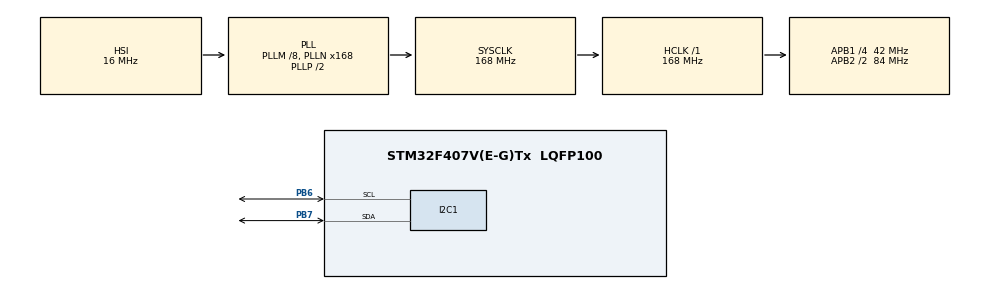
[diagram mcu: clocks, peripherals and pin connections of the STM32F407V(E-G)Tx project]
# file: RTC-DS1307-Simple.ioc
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Mcu.Family=STM32F4
Mcu.Name=STM32F407V(E-G)Tx
Mcu.Package=LQFP100
NVIC.PriorityGroup=NVIC_PRIORITYGROUP_4
PB6.Mode=I2C
PB6.Signal=I2C1_SCL
PB7.Mode=I2C
PB7.Signal=I2C1_SDA
ProjectManager.HeapSize=0x200
ProjectManager.StackSize=0x400
ProjectManager.TargetToolchain=MDK-ARM V5.27
RCC.48MHZClocksFreq_Value=84000000
RCC.AHBFreq_Value=168000000
RCC.APB1CLKDivider=RCC_HCLK_DIV4
RCC.APB1Freq_Value=42000000
RCC.APB1TimFreq_Value=84000000
RCC.APB2CLKDivider=RCC_HCLK_DIV2
RCC.APB2Freq_Value=84000000
RCC.APB2TimFreq_Value=168000000
RCC.CortexFreq_Value=168000000
RCC.HCLKFreq_Value=168000000
RCC.HSE_VALUE=25000000
RCC.HSI_VALUE=16000000
RCC.LSE_VALUE=32768
RCC.PLLM=8
RCC.PLLN=168
RCC.SYSCLKFreq_VALUE=168000000
RCC.SYSCLKSource=RCC_SYSCLKSOURCE_PLLCLK
RCC.VCOOutputFreq_Value=336000000
board=custom

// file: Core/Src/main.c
/* USER CODE BEGIN Header */
/**
  ******************************************************************************
  * @file           : main.c
  * @brief          : Main program body
  ******************************************************************************
  * @attention
  *
  * <h2><center>&copy; Copyright (c) 2023 STMicroelectronics.
  * All rights reserved.</center></h2>
  *
  * This software component is licensed by ST under BSD 3-Clause license,
  * the "License"; You may not use this file except in compliance with the
  * License. You may obtain a copy of the License at:
  *                        opensource.org/licenses/BSD-3-Clause
  *
  ******************************************************************************
  */
/* USER CODE END Header */
#include "main.h"
#include "i2c.h"
#include "gpio.h"

/* USER CODE BEGIN Includes */
#include "ALCD.h"
/* USER CODE END Includes */

/* USER CODE BEGIN PD */
#define DS1307_DEV_ADDR           0xD0
/* USER CODE END PD */

void SystemClock_Config(void);
/* USER CODE BEGIN PFP */
uint8_t RTC_isRunning(void);

void RTC_setTime(uint8_t h, uint8_t m, uint8_t s);
void RTC_setDate(uint8_t y, uint8_t m, uint8_t d, uint8_t weekDay);

void RTC_getTime(uint8_t* h, uint8_t* m, uint8_t* s);
void RTC_getDate(uint8_t* y, uint8_t* m, uint8_t* d, uint8_t* weekDay);

uint8_t bcdToBin(uint8_t val);
uint8_t binToBcd(uint8_t val);

/* USER CODE END PFP */

int main(void)
{
  /* USER CODE BEGIN 1 */
  uint8_t hour;
  uint8_t min;
  uint8_t sec;
  /* USER CODE END 1 */

  /* MCU Configuration--------------------------------------------------------*/

  /* Reset of all peripherals, Initializes the Flash interface and the Systick. */
  HAL_Init();

  /* Configure the system clock */
  SystemClock_Config();

  /* Initialize all configured peripherals */
  MX_GPIO_Init();
  MX_I2C1_Init();
  /* USER CODE BEGIN 2 */
  ALCD_init(16, 2);
  ALCD_clear();
  /* USER CODE END 2 */

  /* Infinite loop */
  /* USER CODE BEGIN WHILE */
  if (!RTC_isRunning()) {
    RTC_setDate(23, 12, 11, 3);
    RTC_setTime(13, 50, 24);
  }

  while (1)
  {

    RTC_getTime(&hour, &min, &sec);
    ALCD_printfXY(2, 0, "%02u:%02u:%02u", hour, min, sec);
    HAL_Delay(1000);
    /* USER CODE END WHILE */

  }
}

void SystemClock_Config(void)
{
  RCC_OscInitTypeDef RCC_OscInitStruct = {0};
  RCC_ClkInitTypeDef RCC_ClkInitStruct = {0};

  /** Configure the main internal regulator output voltage
  */
  __HAL_RCC_PWR_CLK_ENABLE();
  __HAL_PWR_VOLTAGESCALING_CONFIG(PWR_REGULATOR_VOLTAGE_SCALE1);
  /** Initializes the RCC Oscillators according to the specified parameters
  * in the RCC_OscInitTypeDef structure.
  */
  RCC_OscInitStruct.OscillatorType = RCC_OSCILLATORTYPE_HSI;
  RCC_OscInitStruct.HSIState = RCC_HSI_ON;
  RCC_OscInitStruct.HSICalibrationValue = RCC_HSICALIBRATION_DEFAULT;
  RCC_OscInitStruct.PLL.PLLState = RCC_PLL_ON;
  RCC_OscInitStruct.PLL.PLLSource = RCC_PLLSOURCE_HSI;
  RCC_OscInitStruct.PLL.PLLM = 8;
  RCC_OscInitStruct.PLL.PLLN = 168;
  RCC_OscInitStruct.PLL.PLLP = RCC_PLLP_DIV2;
  RCC_OscInitStruct.PLL.PLLQ = 4;
  if (HAL_RCC_OscConfig(&RCC_OscInitStruct) != HAL_OK)
  {
    Error_Handler();
  }
  /** Initializes the CPU, AHB and APB buses clocks
  */
  RCC_ClkInitStruct.ClockType = RCC_CLOCKTYPE_HCLK|RCC_CLOCKTYPE_SYSCLK
                              |RCC_CLOCKTYPE_PCLK1|RCC_CLOCKTYPE_PCLK2;
  RCC_ClkInitStruct.SYSCLKSource = RCC_SYSCLKSOURCE_PLLCLK;
  RCC_ClkInitStruct.AHBCLKDivider = RCC_SYSCLK_DIV1;
  RCC_ClkInitStruct.APB1CLKDivider = RCC_HCLK_DIV4;
  RCC_ClkInitStruct.APB2CLKDivider = RCC_HCLK_DIV2;

  if (HAL_RCC_ClockConfig(&RCC_ClkInitStruct, FLASH_LATENCY_5) != HAL_OK)
  {
    Error_Handler();
  }
}

/* USER CODE BEGIN 4 */
/**
 * 14 (Bin) -> 0x14 (BCD)
 * 37 (Bin) -> 0x37 (BCD)
 */
uint8_t bcdToBin(uint8_t val) {
  return (val & 0x0F) + (((val >> 4) & 0x0F) * 10);
}
uint8_t binToBcd(uint8_t val) {
  return (val % 10) | ((val / 10) << 4);
}

void RTC_setTime(uint8_t h, uint8_t m, uint8_t s) {
  uint8_t buf[3];
  buf[0] = binToBcd(s);
  buf[1] = binToBcd(m);
  buf[2] = binToBcd(h);
  HAL_I2C_Mem_Write(&hi2c1, DS1307_DEV_ADDR, 0, I2C_MEMADD_SIZE_8BIT, buf, sizeof(buf), 1000);
}
void RTC_setDate(uint8_t y, uint8_t m, uint8_t d, uint8_t weekDay) {
  uint8_t buf[4];
  buf[0] = binToBcd(weekDay);
  buf[1] = binToBcd(d);
  buf[2] = binToBcd(m);
  buf[3] = binToBcd(y);
  HAL_I2C_Mem_Write(&hi2c1, DS1307_DEV_ADDR, 3, I2C_MEMADD_SIZE_8BIT, buf, sizeof(buf), 1000);
}

void RTC_getTime(uint8_t* h, uint8_t* m, uint8_t* s) {
  uint8_t buf[3];
  HAL_I2C_Mem_Read(&hi2c1, DS1307_DEV_ADDR, 0, I2C_MEMADD_SIZE_8BIT, buf, sizeof(buf), 1000);

  *s = bcdToBin(buf[0]);
  *m = bcdToBin(buf[1]);
  *h = bcdToBin(buf[2]);
}
void RTC_getDate(uint8_t* y, uint8_t* m, uint8_t* d, uint8_t* weekDay) {
  uint8_t buf[4];
  HAL_I2C_Mem_Read(&hi2c1, DS1307_DEV_ADDR, 0, I2C_MEMADD_SIZE_8BIT, buf, sizeof(buf), 1000);

  *weekDay = bcdToBin(buf[0]);
  *d = bcdToBin(buf[1]);
  *m = bcdToBin(buf[2]);
  *y = bcdToBin(buf[3]);
}
uint8_t RTC_isRunning(void) {
  uint8_t buf[1];
  HAL_I2C_Mem_Read(&hi2c1, DS1307_DEV_ADDR, 0, I2C_MEMADD_SIZE_8BIT, buf, sizeof(buf), 1000);

  return (buf[0] & 0x80) == 0;
}
/* USER CODE END 4 */

void Error_Handler(void)
{
  __disable_irq();
  while (1)
  {
  }
}

/************************ (C) COPYRIGHT STMicroelectronics *****END OF FILE****/
